AUTOSAR XML (schema 00052)
package /apd/LogAndTraceInterface
  log and trace interface TraceIntegrationTest
    namespaces:
      symbol props apd
      symbol props wgres
package /apd/AdaptiveApplicationSwComponentTypes
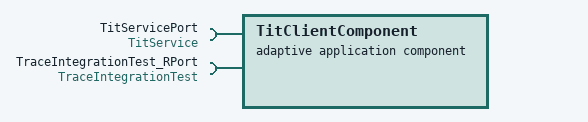
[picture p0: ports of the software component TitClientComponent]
  adaptive application sw component type TitClientComponent
    require port TitServicePort: required-interface=TitService
    require port TraceIntegrationTest_RPort: required-interface=TraceIntegrationTest
package /apd/Executables
  executable RES_TraceIntegrationTest: category=APPLICATION_LEVEL, minimum-timer-granularity=1000
    root sw component prototype RES_TraceIntegrationTest: application-type=TitClientComponent
    trace-switch-configurations:
      trace-message=Test1Msg, trace-switch=TRACE-SWITCH-ARTI-AND-LOG
      trace-message=MethodCall, trace-switch=TRACE-SWITCH-ARTI
